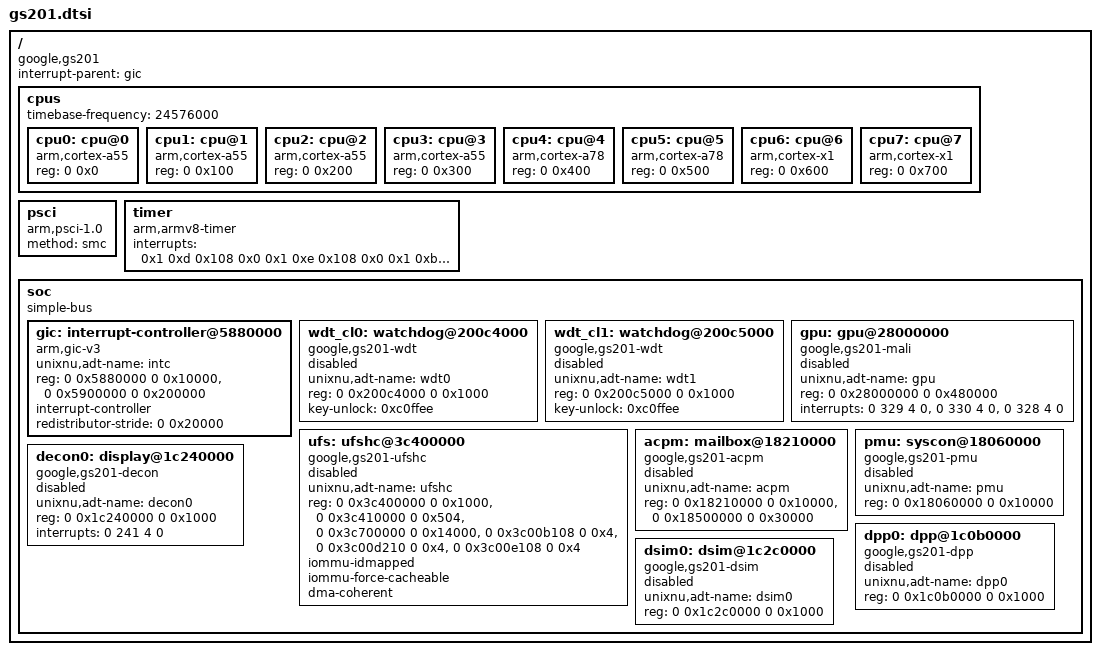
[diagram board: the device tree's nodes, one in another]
// SPDX-License-Identifier: BSD-3-Clause
//
// Google Tensor G2 (gs201) shared SoC resources for UniXNU.
//
// Hardware sources, in evidence order:
//   DTB  — panther factory base device tree (rango BP4A.251205.006,
//          vendor_kernel_boot, panther-lga-base.dtb). Register ranges and
//          interrupt numbers below marked DTB come from that tree.
//   HW   — values proven by direct register observation on panther silicon
//          (ABL splash state, framebuffer scanout, reset recipes).
//   TBD  — not yet verified; the node exists as a placeholder and is disabled.
//
// The stock base tree carries gem5 placeholder CPUs, a 256 MiB memory
// placeholder, and no DECON/DSIM/Mali nodes: ABL and dtbo overlays supply the
// live values. This DTSI records the SoC's real shared resources; the board
// DTS enables what it brings up.

/ {
    compatible = "google,gs201";
    #address-cells = <2>;
    #size-cells = <2>;
    interrupt-parent = <&gic>;

    cpus {
        #address-cells = <2>;
        #size-cells = <0>;
        // System counter frequency; verify against CNTFRQ_EL0 at first light.
        // The ABL hands the core over with architectural timer reads trapped
        // or frozen (CNTHCTL must be opened before any timer use).
        timebase-frequency = <24576000>;

        // Tensor G2: 4x Cortex-A55 (cpu0-3), 2x Cortex-A78 (cpu4-5),
        // 2x Cortex-X1 (cpu6-7). Verified against the live tree cluster
        // layout and the stock kernel's per-cluster watchdogs.
        cpu0: cpu@0 { device_type = "cpu"; compatible = "arm,cortex-a55"; reg = <0 0x0>; };
        cpu1: cpu@1 { device_type = "cpu"; compatible = "arm,cortex-a55"; reg = <0 0x100>; };
        cpu2: cpu@2 { device_type = "cpu"; compatible = "arm,cortex-a55"; reg = <0 0x200>; };
        cpu3: cpu@3 { device_type = "cpu"; compatible = "arm,cortex-a55"; reg = <0 0x300>; };
        cpu4: cpu@4 { device_type = "cpu"; compatible = "arm,cortex-a78"; reg = <0 0x400>; };
        cpu5: cpu@5 { device_type = "cpu"; compatible = "arm,cortex-a78"; reg = <0 0x500>; };
        cpu6: cpu@6 { device_type = "cpu"; compatible = "arm,cortex-x1"; reg = <0 0x600>; };
        cpu7: cpu@7 { device_type = "cpu"; compatible = "arm,cortex-x1"; reg = <0 0x700>; };
    };

    psci {
        compatible = "arm,psci-1.0";
        method = "smc";
    };

    timer {
        compatible = "arm,armv8-timer";
        interrupts = <0x1 0xd 0x108 0x0 0x1 0xe 0x108 0x0 0x1 0xb 0x108 0x0 0x1 0xa 0x108 0x0>;
    };

    soc {
        compatible = "simple-bus";
        #address-cells = <2>;
        #size-cells = <2>;
        ranges;

        // DTB: interrupt-controller@5880000, arm,gic-v3.
        gic: interrupt-controller@5880000 {
            compatible = "arm,gic-v3";
            unixnu,adt-name = "intc";
            reg = <0 0x5880000 0 0x10000>, <0 0x5900000 0 0x200000>;
            #interrupt-cells = <4>;
            #address-cells = <0>;
            interrupt-controller;
            redistributor-stride = <0 0x20000>;
        };

        // DTB: watchdog_cl0/watchdog_cl1, google,wdt, key-locked blocks
        // (write 0xc0ffee to base+0x04 to unlock, 0 to relock). On panther
        // silicon, from the fastboot-boot context: enable-time violation
        // resets at these addresses fire reliably; steady countdown does
        // not. See the device record before relying on either.
        wdt_cl0: watchdog@200c4000 {
            compatible = "google,gs201-wdt";
            unixnu,adt-name = "wdt0";
            reg = <0 0x200c4000 0 0x1000>;
            key-unlock = <0xc0ffee>;
            status = "disabled";
        };

        wdt_cl1: watchdog@200c5000 {
            compatible = "google,gs201-wdt";
            unixnu,adt-name = "wdt1";
            reg = <0 0x200c5000 0 0x1000>;
            key-unlock = <0xc0ffee>;
            status = "disabled";
        };

        // DTB: ufs@3c400000, google,ufshc, six register windows.
        ufs: ufshc@3c400000 {
            compatible = "google,gs201-ufshc";
            unixnu,adt-name = "ufshc";
            reg = <0 0x3c400000 0 0x1000>, <0 0x3c410000 0 0x504>,
                  <0 0x3c700000 0 0x14000>, <0 0x3c00b108 0 0x4>,
                  <0 0x3c00d210 0 0x4>, <0 0x3c00e108 0 0x4>;
            reg-names = "ufs_hc", "ufs_top", "ufs_phy_sram",
                        "psm_status_hsios", "psm_status_ufs_hc", "psm_status_ufs_phy";
            iommu-idmapped;
            iommu-force-cacheable;
            dma-coherent;
            status = "disabled";
        };

        // HW + omarchy (linux-omarchy ran panthor on this exact board):
        // Mali G710 MC10, Valhall arch 10.8 CSF. Needs the CSF firmware
        // (linux-firmware arm/mali/arch10.8/mali_csffw.bin); the device's
        // own kbase-ABI firmware blob is incompatible. PMU G3D registers
        // (0x18061e00..0x18062010) are EL3-gated — an NS read crashes the
        // SoC. Clock/DVFS go through ACPM, never direct CMU_G3D writes.
        gpu: gpu@28000000 {
            compatible = "google,gs201-mali", "arm,mali-valhall-csf";
            unixnu,adt-name = "gpu";
            reg = <0 0x28000000 0 0x480000>;
            interrupts = <0 329 4 0>, <0 330 4 0>, <0 328 4 0>;
            interrupt-names = "job", "mmu", "gpu";
            status = "disabled";
        };

        // HW: ACPM (APM) mailbox and its SRAM; DVFS message IDs observed
        // working on panther: 0x0B040005 (G3D shaders), 0x0B040006 (G3D L2).
        acpm: mailbox@18210000 {
            compatible = "google,gs201-acpm";
            unixnu,adt-name = "acpm";
            reg = <0 0x18210000 0 0x10000>, <0 0x18500000 0 0x30000>;
            reg-names = "mailbox", "sram";
            status = "disabled";
        };

        // HW: PMU syscon. Reboot controller; SYSIP_DAT0 at +0x810 (write
        // 0xfa before reset to land in the bootloader). PS_HOLD at +0x3e9c
        // bit 8. PMU_ALIVE writes are EL3-gated on this SoC: direct MMIO
        // from EL1/EL2 is ignored (observed), SMC 0x82000504 performs a
        // fast deterministic reset.
        pmu: syscon@18060000 {
            compatible = "google,gs201-pmu", "syscon";
            unixnu,adt-name = "pmu";
            reg = <0 0x18060000 0 0x10000>;
            status = "disabled";
        };

        // HW: the ABL-owned display pipeline (live DECON/DSIM/DPP nodes are
        // installed by dtbo overlays; the stock base tree's sswrp_dpu@ec00000
        // Verisilicon subsystem is NOT what ABL scans out of). DECON0 base,
        // DPP0 RDMA and DSIM0 link verified by register observation while
        // ABL held the splash. DSIM0 shares the DECON0 2 MiB gate: touching
        // its registers while the block is clock-gated raises an external
        // abort (twice reproduced). The cont_splash framebuffer lives at
        // 0xfac00000 (XRGB8888, 1080x2400, stride 4320) — the board DTS
        // reserves it.
        decon0: display@1c240000 {
            compatible = "google,gs201-decon";
            unixnu,adt-name = "decon0";
            reg = <0 0x1c240000 0 0x1000>;
            interrupts = <0 241 4 0>;
            status = "disabled";
        };

        dpp0: dpp@1c0b0000 {
            compatible = "google,gs201-dpp";
            unixnu,adt-name = "dpp0";
            reg = <0 0x1c0b0000 0 0x1000>;
            status = "disabled";
        };

        dsim0: dsim@1c2c0000 {
            compatible = "google,gs201-dsim";
            unixnu,adt-name = "dsim0";
            reg = <0 0x1c2c0000 0 0x1000>;
            status = "disabled";
        };
    };
};
